# STM32H743 register map
File version: 2.4
CPU: CM7 r0p1, little endian, MPU, FPU, 4 interrupt priority bits
Registers are 32-bit, read-write, reset 0x0 unless marked. A register's access mark holds for its fields unless they carry their own. Offsets are from the block's base; [hi:lo] are bit positions; {n}, {i} and the like mark numbered series.

## USART1 — 通用同步异步收发器
Base 0x40011000
Same registers: USART2 0x40004400, USART3 0x40004800, UART4 0x40004C00, UART5 0x40005000, UART7 0x40007800, UART8 0x40007C00, USART6 0x40011400
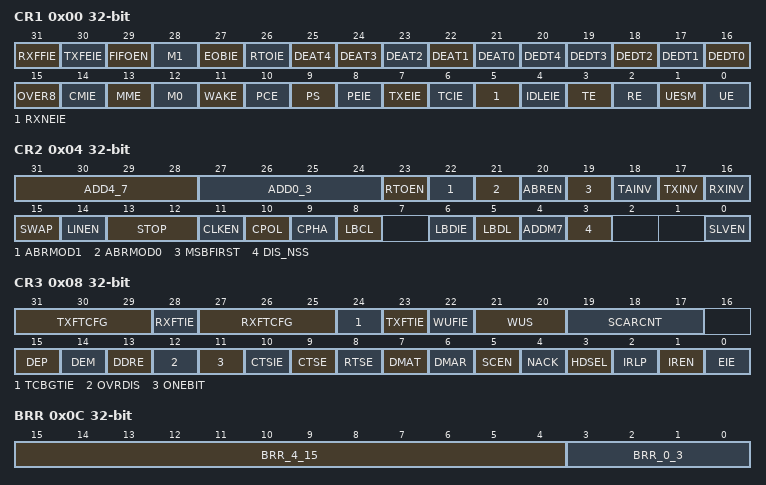
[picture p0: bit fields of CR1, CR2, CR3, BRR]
0x00 CR1 — 控制寄存器 1
  [31] RXFFIE — RXFIFO 满中断使能
  [30] TXFEIE — TXFIFO 空中断使能
  [29] FIFOEN — FIFO 模式使能
  [28] M1 — 字长
  [27] EOBIE — 块结束中断使能
  [26] RTOIE — 接收超时中断使能
  [25] DEAT4 — 驱动器使能建立时间
  [n+21] DEAT{n} (n=0..3)
  [20] DEDT4 — 驱动器使能释放时间
  [n+16] DEDT{n} (n=0..3)
  [15] OVER8 — 过采样模式
  [14] CMIE — 字符匹配中断使能
  [13] MME — 静默模式使能
  [12] M0 — 字长
  [11] WAKE — 接收器唤醒方式
  [10] PCE — 奇偶校验控制使能
  [9] PS — 奇偶校验选择
  [8] PEIE — 奇偶校验错误中断使能
  [7] TXEIE — 发送数据寄存器空中断使能
  [6] TCIE — 发送完成中断使能
  [5] RXNEIE — RXNE 中断使能
  [4] IDLEIE — 空闲线路检测中断使能
  [3] TE — 发送器使能
  [2] RE — 接收器使能
  [1] UESM — 停止模式下 USART 使能
  [0] UE — USART 使能
0x04 CR2 — 控制寄存器 2
  [31:28] ADD4_7 — USART 节点地址（高 4 位）
  [27:24] ADD0_3 — USART 节点地址（低 4 位）
  [23] RTOEN — 接收超时使能
  [22] ABRMOD1 — 自动波特率模式
  [21] ABRMOD0
  [20] ABREN — 自动波特率使能
  [19] MSBFIRST — 最高位优先
  [18] TAINV — 二进制数据反转
  [17] TXINV — TX 引脚有效电平反转
  [16] RXINV — RX 引脚有效电平反转
  [15] SWAP — TX/RX 引脚交换
  [14] LINEN — LIN 模式使能
  [13:12] STOP — 停止位
  [11] CLKEN — 时钟使能
  [10] CPOL — 时钟极性
  [9] CPHA — 时钟相位
  [8] LBCL — 最后一位时钟脉冲输出
  [6] LBDIE — LIN 断开检测中断使能
  [5] LBDL — LIN 断开检测长度
  [4] ADDM7 — 7 位地址检测 / 4 位地址检测
  [3] DIS_NSS — 当 DIS_NSS 位置位时，忽略 NSS 引脚输入
  [0] SLVEN — 同步从模式使能
0x08 CR3 — 控制寄存器 3
  [31:29] TXFTCFG — TXFIFO 阈值配置
  [28] RXFTIE — RXFIFO 阈值中断使能
  [27:25] RXFTCFG — 接收 FIFO 阈值配置
  [24] TCBGTIE — 保护时间前发送完成中断使能
  [23] TXFTIE — TXFIFO 阈值中断使能
  [22] WUFIE — 停止模式唤醒中断使能
  [21:20] WUS — 停止模式唤醒中断标志选择
  [19:17] SCARCNT — 智能卡自动重试次数
  [15] DEP — 驱动器使能极性选择
  [14] DEM — 驱动器使能模式
  [13] DDRE — 接收错误时禁止 DMA
  [12] OVRDIS — 溢出禁止
  [11] ONEBIT — 单采样位方式使能
  [10] CTSIE — CTS 中断使能
  [9] CTSE — CTS 使能
  [8] RTSE — RTS 使能
  [7] DMAT — DMA 发送使能
  [6] DMAR — DMA 接收使能
  [5] SCEN — 智能卡模式使能
  [4] NACK — 智能卡 NACK 使能
  [3] HDSEL — 半双工选择
  [2] IRLP — 红外低功耗
  [1] IREN — 红外模式使能
  [0] EIE — 错误中断使能
0x0C BRR — 波特率寄存器
  [15:4] BRR_4_15 — 分频系数整数部分（DIV_Mantissa）
  [3:0] BRR_0_3 — 分频系数小数部分（DIV_Fraction）
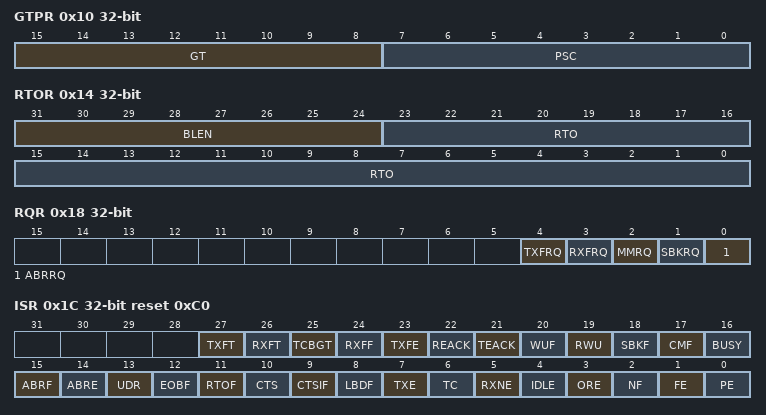
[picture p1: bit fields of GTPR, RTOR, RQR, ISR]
0x10 GTPR — 保护时间与预分频器寄存器
  [15:8] GT — 保护时间值
  [7:0] PSC — 预分频器值
0x14 RTOR — 接收超时寄存器
  [31:24] BLEN — 块长度
  [23:0] RTO — 接收超时值
0x18 RQR wo — 请求寄存器
  [4] TXFRQ — 发送数据刷新请求
  [3] RXFRQ — 接收数据刷新请求
  [2] MMRQ — 静默模式请求
  [1] SBKRQ — 发送断开帧请求
  [0] ABRRQ — 自动波特率请求
0x1C ISR ro reset 0xC0 — 中断与状态寄存器
  [27] TXFT — TXFIFO 阈值标志
  [26] RXFT — RXFIFO 阈值标志
  [25] TCBGT — 保护时间前发送完成标志
  [24] RXFF — RXFIFO 满标志
  [23] TXFE — TXFIFO 空标志
  [22] REACK — 接收器使能确认标志
  [21] TEACK — 发送器使能确认标志
  [20] WUF — 停止模式唤醒标志
  [19] RWU — 接收器唤醒标志
  [18] SBKF — 发送断开帧标志
  [17] CMF — 字符匹配标志
  [16] BUSY — 忙标志
  [15] ABRF — 自动波特率检测完成标志
  [14] ABRE — 自动波特率错误标志
  [13] UDR — SPI 从模式下溢错误标志
  [12] EOBF — 块结束标志
  [11] RTOF — 接收超时标志
  [10] CTS — CTS 标志
  [9] CTSIF — CTS 中断标志
  [8] LBDF — LIN 断开检测标志
  [7] TXE — 发送数据寄存器空
  [6] TC — 发送完成
  [5] RXNE — 接收数据寄存器非空
  [4] IDLE — 空闲线路检测
  [3] ORE — 溢出错误
  [2] NF — 噪声错误标志
  [1] FE — 帧错误
  [0] PE — 奇偶校验错误
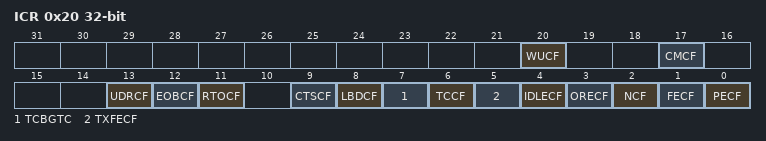
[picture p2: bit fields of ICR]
0x20 ICR wo — 中断标志清除寄存器
  [20] WUCF — 停止模式唤醒标志清除
  [17] CMCF — 字符匹配标志清除
  [13] UDRCF — SPI 从模式下溢标志清除
  [12] EOBCF — 块结束标志清除
  [11] RTOCF — 接收超时标志清除
  [9] CTSCF — CTS 标志清除
  [8] LBDCF — LIN 断开检测标志清除
  [7] TCBGTC — 保护时间前发送完成标志清除
  [6] TCCF — 发送完成标志清除
  [5] TXFECF — TXFIFO 空标志清除
  [4] IDLECF — 空闲线路检测标志清除
  [3] ORECF — 溢出错误标志清除
  [2] NCF — 噪声检测标志清除
  [1] FECF — 帧错误标志清除
  [0] PECF — 奇偶校验错误标志清除
0x24 RDR ro — 接收数据寄存器
  [8:0] RDR — 接收数据值
0x28 TDR — 发送数据寄存器
  [8:0] TDR — 发送数据值
0x2C PRESC — USART 预分频器寄存器
  [3:0] PRESCALER — 时钟预分频器

## CAN_CCU — 时钟校准单元（CCU）寄存器
Base 0x4000A800
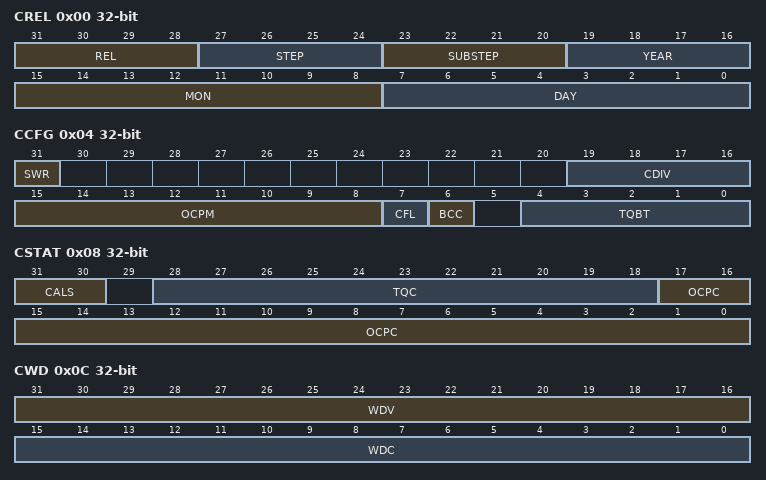
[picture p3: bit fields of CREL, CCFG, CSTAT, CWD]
0x00 CREL — 时钟校准单元内核版本寄存器
  [31:28] REL — 内核版本号
  [27:24] STEP — 内核版本步进号
  [23:20] SUBSTEP — 内核版本子步进号
  [19:16] YEAR — 时间戳：年
  [15:8] MON — 时间戳：月
  [7:0] DAY — 时间戳：日
0x04 CCFG — 校准配置寄存器
  [31] SWR — 软件复位
  [19:16] CDIV — 时钟分频器
  [15:8] OCPM — 振荡器时钟周期最小值
  [7] CFL — 校准域长度
  [6] BCC — 旁路时钟校准
  [4:0] TQBT — 每比特时间的时间份额数
0x08 CSTAT — 校准状态寄存器
  [31:30] CALS — 校准状态
  [28:18] TQC — 时间份额计数器
  [17:0] OCPC — 振荡器时钟周期计数器
0x0C CWD — 校准看门狗寄存器
  [31:16] WDV — 看门狗计数值（WDV）
  [15:0] WDC — 看门狗计数器（WDC）
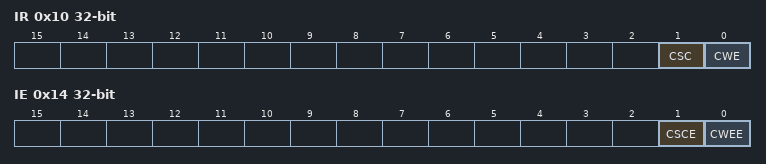
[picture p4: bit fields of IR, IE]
0x10 IR — 时钟校准单元中断寄存器
  [1] CSC — 校准状态变更
  [0] CWE — 校准看门狗事件
0x14 IE — 时钟校准单元中断使能寄存器
  [1] CSCE — 校准状态变更使能
  [0] CWEE — 校准看门狗事件使能
